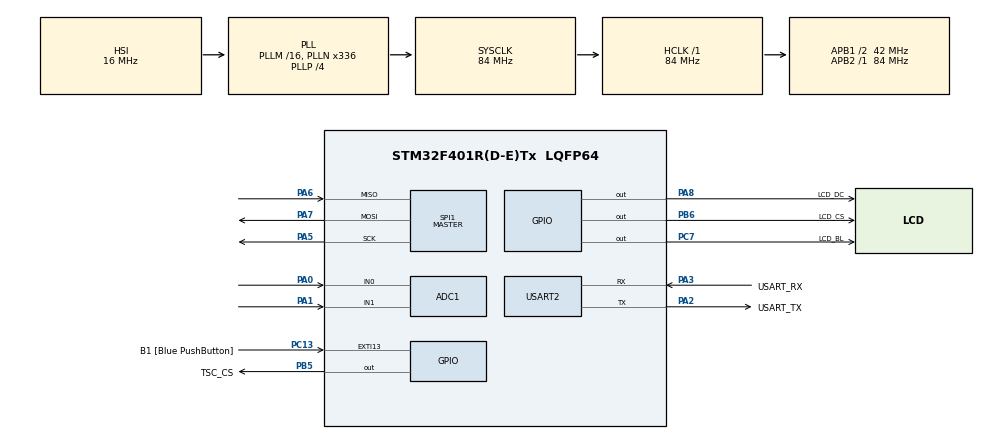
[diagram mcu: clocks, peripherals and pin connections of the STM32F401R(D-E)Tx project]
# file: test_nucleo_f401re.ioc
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ADC1.Channel-5\#ChannelRegularConversion=ADC_CHANNEL_0
ADC1.Channel-6\#ChannelRegularConversion=ADC_CHANNEL_1
ADC1.DMAContinuousRequests=ENABLE
ADC1.EOCSelection=ADC_EOC_SINGLE_CONV
ADC1.EnableAnalogWatchDog=true
ADC1.ExternalTrigConv=ADC_EXTERNALTRIGCONV_T2_TRGO
ADC1.HighThreshold=2048
ADC1.ITMode=ENABLE
ADC1.LowThreshold=1024
ADC1.NbrOfConversion=2
ADC1.NbrOfConversionFlag=1
ADC1.Rank-5\#ChannelRegularConversion=1
ADC1.Rank-6\#ChannelRegularConversion=2
ADC1.SamplingTime-5\#ChannelRegularConversion=ADC_SAMPLETIME_3CYCLES
ADC1.SamplingTime-6\#ChannelRegularConversion=ADC_SAMPLETIME_3CYCLES
ADC1.master=1
Dma.ADC1.0.Direction=DMA_PERIPH_TO_MEMORY
Dma.ADC1.0.FIFOMode=DMA_FIFOMODE_DISABLE
Dma.ADC1.0.Instance=DMA2_Stream0
Dma.ADC1.0.MemDataAlignment=DMA_MDATAALIGN_HALFWORD
Dma.ADC1.0.MemInc=DMA_MINC_ENABLE
Dma.ADC1.0.Mode=DMA_CIRCULAR
Dma.ADC1.0.PeriphDataAlignment=DMA_PDATAALIGN_HALFWORD
Dma.ADC1.0.PeriphInc=DMA_PINC_DISABLE
Dma.ADC1.0.Priority=DMA_PRIORITY_LOW
Dma.Request0=ADC1
FREERTOS.BinarySemaphores01=semSpi,Dynamic,NULL
FREERTOS.Queues01=queueTscUi,1,struct sQueueTscUi,0,Dynamic,NULL,NULL;queueUiScope,1,struct sQueueUiScope,0,Dynamic,NULL,NULL
FREERTOS.Tasks01=defaultTask,24,128,StartDefaultTask,Default,NULL,Dynamic,NULL,NULL;taskTsc,24,128,StartTaskTsc,As external,NULL,Dynamic,NULL,NULL;taskUi,24,1024,StartTaskUi,As external,NULL,Dynamic,NULL,NULL;taskScope,24,128,StartTaskScope,As external,NULL,Dynamic,NULL,NULL
FREERTOS.configUSE_NEWLIB_REENTRANT=1
Mcu.Family=STM32F4
Mcu.Name=STM32F401R(D-E)Tx
Mcu.Package=LQFP64
NVIC.ADC_IRQn=true\:5\:0\:false\:false\:true\:true\:true\:true\:true
NVIC.DMA2_Stream0_IRQn=true\:5\:0\:false\:false\:true\:true\:false\:true\:true
NVIC.PriorityGroup=NVIC_PRIORITYGROUP_4
NVIC.TIM1_UP_TIM10_IRQn=true\:15\:0\:false\:false\:true\:false\:false\:true\:true
NVIC.TIM3_IRQn=true\:5\:0\:false\:false\:true\:true\:true\:true\:true
NVIC.TimeBase=TIM1_UP_TIM10_IRQn
NVIC.TimeBaseIP=TIM1
PA0-WKUP.Signal=ADCx_IN0
PA1.Signal=ADCx_IN1
PA13.GPIO_Label=TMS
PA13.Mode=Trace_Asynchronous_SW
PA13.Signal=SYS_JTMS-SWDIO
PA14.GPIO_Label=TCK
PA14.Mode=Trace_Asynchronous_SW
PA14.Signal=SYS_JTCK-SWCLK
PA2.GPIO_Label=USART_TX
PA2.GPIO_Mode=GPIO_MODE_AF_PP
PA2.GPIO_PuPd=GPIO_NOPULL
PA2.GPIO_Speed=GPIO_SPEED_FREQ_LOW
PA2.Mode=Asynchronous
PA2.Signal=USART2_TX
PA3.GPIO_Label=USART_RX
PA3.GPIO_Mode=GPIO_MODE_AF_PP
PA3.GPIO_PuPd=GPIO_NOPULL
PA3.GPIO_Speed=GPIO_SPEED_FREQ_LOW
PA3.Mode=Asynchronous
PA3.Signal=USART2_RX
PA5.Mode=Full_Duplex_Master
PA5.Signal=SPI1_SCK
PA6.Mode=Full_Duplex_Master
PA6.Signal=SPI1_MISO
PA7.Mode=Full_Duplex_Master
PA7.Signal=SPI1_MOSI
PA8.GPIO_Label=LCD_DC
PA8.Signal=GPIO_Output
PB3.Mode=Trace_Asynchronous_SW
PB3.Signal=SYS_JTDO-SWO
PB5.GPIO_Label=TSC_CS
PB5.GPIO_PuPd=GPIO_PULLUP
PB5.Signal=GPIO_Output
PB6.GPIO_Label=LCD_CS
PB6.GPIO_PuPd=GPIO_PULLUP
PB6.Signal=GPIO_Output
PC13-ANTI_TAMP.GPIO_Label=B1 [Blue PushButton]
PC13-ANTI_TAMP.GPIO_ModeDefaultEXTI=GPIO_MODE_IT_FALLING
PC13-ANTI_TAMP.GPIO_PuPd=GPIO_NOPULL
PC13-ANTI_TAMP.Signal=GPXTI13
PC14-OSC32_IN.Mode=LSE-External-Oscillator
PC14-OSC32_IN.Signal=RCC_OSC32_IN
PC15-OSC32_OUT.Mode=LSE-External-Oscillator
PC15-OSC32_OUT.Signal=RCC_OSC32_OUT
PC7.GPIO_Label=LCD_BL
PC7.Signal=GPIO_Output
PH0\ -\ OSC_IN.Mode=HSE-External-Clock-Source
PH0\ -\ OSC_IN.Signal=RCC_OSC_IN
PH1\ -\ OSC_OUT.Mode=HSE-External-Clock-Source
PH1\ -\ OSC_OUT.Signal=RCC_OSC_OUT
ProjectManager.HeapSize=0x200
ProjectManager.StackSize=0x400
ProjectManager.TargetToolchain=STM32CubeIDE
RCC.48MHZClocksFreq_Value=48000000
RCC.AHBFreq_Value=84000000
RCC.APB1CLKDivider=RCC_HCLK_DIV2
RCC.APB1Freq_Value=42000000
RCC.APB1TimFreq_Value=84000000
RCC.APB2Freq_Value=84000000
RCC.APB2TimFreq_Value=84000000
RCC.CortexFreq_Value=84000000
RCC.HCLKFreq_Value=84000000
RCC.HSE_VALUE=8000000
RCC.HSI_VALUE=16000000
RCC.PLLN=336
RCC.PLLP=RCC_PLLP_DIV4
RCC.PLLQ=7
RCC.SYSCLKFreq_VALUE=84000000
RCC.SYSCLKSource=RCC_SYSCLKSOURCE_PLLCLK
RCC.VCOOutputFreq_Value=336000000
SH.ADCx_IN0.0=ADC1_IN0,IN0
SH.ADCx_IN1.0=ADC1_IN1,IN1
SPI1.BaudRatePrescaler=SPI_BAUDRATEPRESCALER_4
SPI1.Direction=SPI_DIRECTION_2LINES
SPI1.Mode=SPI_MODE_MASTER
SPI1.VirtualType=VM_MASTER
TIM2.Period=84
TIM2.TIM_MasterOutputTrigger=TIM_TRGO_UPDATE
TIM3.Period=84*512
USART2.VirtualMode=VM_ASYNC
VP_FREERTOS_VS_CMSIS_V2.Mode=CMSIS_V2
VP_SYS_VS_tim1.Mode=TIM1
VP_TIM2_VS_ClockSourceINT.Mode=Internal
VP_TIM3_VS_ClockSourceINT.Mode=Internal
VP_TIM3_VS_OPM.Mode=OPM_bit
board=NUCLEO-F401RE

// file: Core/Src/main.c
/* USER CODE BEGIN Header */
/**
  ******************************************************************************
  * @file           : main.c
  * @brief          : Main program body
  ******************************************************************************
  * @attention
  *
  * Copyright (c) 2023 STMicroelectronics.
  * All rights reserved.
  *
  * This software is licensed under terms that can be found in the LICENSE file
  * in the root directory of this software component.
  * If no LICENSE file comes with this software, it is provided AS-IS.
  *
  ******************************************************************************
  */
/* USER CODE END Header */
#include "main.h"
#include "cmsis_os.h"
#include "adc.h"
#include "dma.h"
#include "spi.h"
#include "tim.h"
#include "usart.h"
#include "gpio.h"

void SystemClock_Config(void);
void MX_FREERTOS_Init(void);

int main(void)
{

  /* MCU Configuration--------------------------------------------------------*/

  /* Reset of all peripherals, Initializes the Flash interface and the Systick. */
  HAL_Init();

  /* Configure the system clock */
  SystemClock_Config();

  /* Initialize all configured peripherals */
  MX_GPIO_Init();
  MX_DMA_Init();
  MX_USART2_UART_Init();
  MX_SPI1_Init();
  MX_ADC1_Init();
  MX_TIM2_Init();
  MX_TIM3_Init();

  /* Init scheduler */
  osKernelInitialize();  /* Call init function for freertos objects (in freertos.c) */
  MX_FREERTOS_Init();

  /* Start scheduler */
  osKernelStart();

  /* We should never get here as control is now taken by the scheduler */
  /* Infinite loop */
  while (1)
  {

  }
}

void SystemClock_Config(void)
{
  RCC_OscInitTypeDef RCC_OscInitStruct = {0};
  RCC_ClkInitTypeDef RCC_ClkInitStruct = {0};

  /** Configure the main internal regulator output voltage
  */
  __HAL_RCC_PWR_CLK_ENABLE();
  __HAL_PWR_VOLTAGESCALING_CONFIG(PWR_REGULATOR_VOLTAGE_SCALE2);

  /** Initializes the RCC Oscillators according to the specified parameters
  * in the RCC_OscInitTypeDef structure.
  */
  RCC_OscInitStruct.OscillatorType = RCC_OSCILLATORTYPE_HSI;
  RCC_OscInitStruct.HSIState = RCC_HSI_ON;
  RCC_OscInitStruct.HSICalibrationValue = RCC_HSICALIBRATION_DEFAULT;
  RCC_OscInitStruct.PLL.PLLState = RCC_PLL_ON;
  RCC_OscInitStruct.PLL.PLLSource = RCC_PLLSOURCE_HSI;
  RCC_OscInitStruct.PLL.PLLM = 16;
  RCC_OscInitStruct.PLL.PLLN = 336;
  RCC_OscInitStruct.PLL.PLLP = RCC_PLLP_DIV4;
  RCC_OscInitStruct.PLL.PLLQ = 7;
  if (HAL_RCC_OscConfig(&RCC_OscInitStruct) != HAL_OK)
  {
    Error_Handler();
  }

  /** Initializes the CPU, AHB and APB buses clocks
  */
  RCC_ClkInitStruct.ClockType = RCC_CLOCKTYPE_HCLK|RCC_CLOCKTYPE_SYSCLK
                              |RCC_CLOCKTYPE_PCLK1|RCC_CLOCKTYPE_PCLK2;
  RCC_ClkInitStruct.SYSCLKSource = RCC_SYSCLKSOURCE_PLLCLK;
  RCC_ClkInitStruct.AHBCLKDivider = RCC_SYSCLK_DIV1;
  RCC_ClkInitStruct.APB1CLKDivider = RCC_HCLK_DIV2;
  RCC_ClkInitStruct.APB2CLKDivider = RCC_HCLK_DIV1;

  if (HAL_RCC_ClockConfig(&RCC_ClkInitStruct, FLASH_LATENCY_2) != HAL_OK)
  {
    Error_Handler();
  }
}

void HAL_TIM_PeriodElapsedCallback(TIM_HandleTypeDef *htim)
{
  if (htim->Instance == TIM1) {
    HAL_IncTick();
  }
}

void Error_Handler(void)
{
  __disable_irq();
  while (1)
  {
  }
}

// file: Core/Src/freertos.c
/* USER CODE BEGIN Header */
/**
  ******************************************************************************
  * File Name          : freertos.c
  * Description        : Code for freertos applications
  ******************************************************************************
  * @attention
  *
  * Copyright (c) 2023 STMicroelectronics.
  * All rights reserved.
  *
  * This software is licensed under terms that can be found in the LICENSE file
  * in the root directory of this software component.
  * If no LICENSE file comes with this software, it is provided AS-IS.
  *
  ******************************************************************************
  */
/* USER CODE END Header */

#include "FreeRTOS.h"
#include "task.h"
#include "main.h"
#include "cmsis_os.h"

/* Definitions for defaultTask */
osThreadId_t defaultTaskHandle;
const osThreadAttr_t defaultTask_attributes = {
  .name = "defaultTask",
  .stack_size = 128 * 4,
  .priority = (osPriority_t) osPriorityNormal,
};
/* Definitions for taskTsc */
osThreadId_t taskTscHandle;
const osThreadAttr_t taskTsc_attributes = {
  .name = "taskTsc",
  .stack_size = 128 * 4,
  .priority = (osPriority_t) osPriorityNormal,
};
/* Definitions for taskUi */
osThreadId_t taskUiHandle;
const osThreadAttr_t taskUi_attributes = {
  .name = "taskUi",
  .stack_size = 1024 * 4,
  .priority = (osPriority_t) osPriorityNormal,
};
/* Definitions for taskScope */
osThreadId_t taskScopeHandle;
const osThreadAttr_t taskScope_attributes = {
  .name = "taskScope",
  .stack_size = 128 * 4,
  .priority = (osPriority_t) osPriorityNormal,
};
/* Definitions for queueTscUi */
osMessageQueueId_t queueTscUiHandle;
const osMessageQueueAttr_t queueTscUi_attributes = {
  .name = "queueTscUi"
};
/* Definitions for queueUiScope */
osMessageQueueId_t queueUiScopeHandle;
const osMessageQueueAttr_t queueUiScope_attributes = {
  .name = "queueUiScope"
};
/* Definitions for semSpi */
osSemaphoreId_t semSpiHandle;
const osSemaphoreAttr_t semSpi_attributes = {
  .name = "semSpi"
};

void StartDefaultTask(void *argument);
extern void StartTaskTsc(void *argument);
extern void StartTaskUi(void *argument);
extern void StartTaskScope(void *argument);

void MX_FREERTOS_Init(void); /* (MISRA C 2004 rule 8.1) */

void MX_FREERTOS_Init(void) {

  /* Create the semaphores(s) */
  /* creation of semSpi */
  semSpiHandle = osSemaphoreNew(1, 1, &semSpi_attributes);

  /* USER CODE BEGIN RTOS_SEMAPHORES */
  /* add semaphores, ... */
  osSemaphoreAcquire( semSpiHandle, portMAX_DELAY );
  /* USER CODE END RTOS_SEMAPHORES */

  /* Create the queue(s) */
  /* creation of queueTscUi */
  queueTscUiHandle = osMessageQueueNew (1, sizeof(struct sQueueTscUi), &queueTscUi_attributes);

  /* creation of queueUiScope */
  queueUiScopeHandle = osMessageQueueNew (1, sizeof(struct sQueueUiScope), &queueUiScope_attributes);

  /* Create the thread(s) */
  /* creation of defaultTask */
  defaultTaskHandle = osThreadNew(StartDefaultTask, NULL, &defaultTask_attributes);

  /* creation of taskTsc */
  taskTscHandle = osThreadNew(StartTaskTsc, NULL, &taskTsc_attributes);

  /* creation of taskUi */
  taskUiHandle = osThreadNew(StartTaskUi, NULL, &taskUi_attributes);

  /* creation of taskScope */
  taskScopeHandle = osThreadNew(StartTaskScope, NULL, &taskScope_attributes);

}

void StartDefaultTask(void *argument)
{
  for(;;)
  {
    osDelay(1);
  }
}
